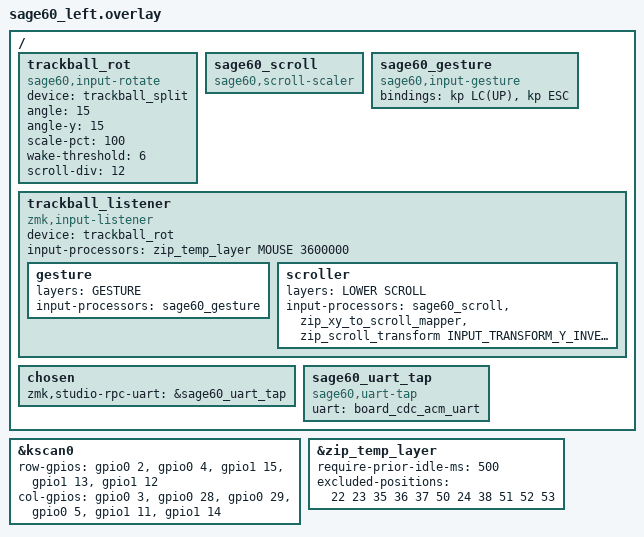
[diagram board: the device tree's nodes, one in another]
/*
 * Copyright (c) 2026 Diwamoto_
 * SPDX-License-Identifier: MIT
 *
 * Sage60 MX - left half (central)
 * Source: pcb/mx_main/mx.kicad_sch  (XIAO nRF52840 = U1)
 *
 *  COL0 -> U1/2  P0.03 (D1)      ROW0 -> U1/1  P0.02 (D0)
 *  COL1 -> U1/3  P0.28 (D2)      ROW1 -> U1/5  P0.04 (D4)
 *  COL2 -> U1/4  P0.29 (D3)      ROW2 -> U1/11 P1.15 (D10)
 *  COL3 -> U1/6  P0.05 (D5)      ROW3 -> U1/9  P1.13 (D8)
 *  COL4 -> U1/7  P1.11 (D6)      ROW4 -> U1/8  P1.12 (D7)
 *  COL5 -> U1/10 P1.14 (D9)
 *
 * diode-direction = col2row  ->  columns are driven (outputs),
 *                                rows are sensed (inputs, pull-down).
 */

#include "sage60.dtsi"
#include <input/processors.dtsi>
#include <dt-bindings/zmk/input_transform.h>
#include <behaviors.dtsi>
#include <dt-bindings/zmk/keys.h>

&kscan0 {
    row-gpios
        = <&gpio0  2 (GPIO_ACTIVE_HIGH | GPIO_PULL_DOWN)>   /* ROW0 P0.02 */
        , <&gpio0  4 (GPIO_ACTIVE_HIGH | GPIO_PULL_DOWN)>   /* ROW1 P0.04 */
        , <&gpio1 15 (GPIO_ACTIVE_HIGH | GPIO_PULL_DOWN)>   /* ROW2 P1.15 */
        , <&gpio1 13 (GPIO_ACTIVE_HIGH | GPIO_PULL_DOWN)>   /* ROW3 P1.13 */
        , <&gpio1 12 (GPIO_ACTIVE_HIGH | GPIO_PULL_DOWN)>   /* ROW4 P1.12 */
        ;

    col-gpios
        = <&gpio0  3 GPIO_ACTIVE_HIGH>   /* COL0 P0.03 */
        , <&gpio0 28 GPIO_ACTIVE_HIGH>   /* COL1 P0.28 */
        , <&gpio0 29 GPIO_ACTIVE_HIGH>   /* COL2 P0.29 */
        , <&gpio0  5 GPIO_ACTIVE_HIGH>   /* COL3 P0.05 */
        , <&gpio1 11 GPIO_ACTIVE_HIGH>   /* COL4 P1.11 */
        , <&gpio1 14 GPIO_ACTIVE_HIGH>   /* COL5 P1.14 */
        ;
};

/* Layer numbers from sage60.keymap. */
#define LOWER  1
#define MOUSE  4
#define SCROLL 5
#define GESTURE 6

/* Moving the ball turns on MOUSE and it stays on (1 h timeout, i.e. never in
 * practice) until a key outside the mouse keys (L back, P forward, ; left,
 * | right, ' scroll, / gesture) and the modifiers (Ctrl, both
 * Shifts, Alt, Cmd, for Cmd-click etc.) is pressed. Typing blocks it for
 * 500 ms so a nudged ball doesn't hijack the home row. */
&zip_temp_layer {
    require-prior-idle-ms = <500>;
    excluded-positions = <22 23 35 36 37 50 /* mouse keys */
                          24 38 51 52 53>; /* LCTRL LSHFT RSHFT LALT LGUI */
};

/ {
    /* The hand rolls the ball at a slant, so a "straight" sideways roll
     * drifts vertically. Positive angle turns motion clockwise on screen.
     * These are defaults: case/site/tune.html changes them over USB and the
     * values are kept in flash (settings_reset clears them). */
    trackball_rot: trackball_rot {
        compatible = "sage60,input-rotate";
        device = <&trackball_split>;
        angle = <15>;   /* sideways rolls */
        angle-y = <15>; /* up/down rolls */
        scale-pct = <100>;
        /* Ignore the first few counts after the ball rests, so typing
         * vibration doesn't nudge the cursor. Raise if it still does. */
        wake-threshold = <6>;
        scroll-div = <12>; /* ball counts per scroll step, lower is faster */
    };

    sage60_scroll: sage60_scroll {
        compatible = "sage60,scroll-scaler";
        #input-processor-cells = <0>;
    };

    /* Hold / and roll up for Mission Control, down for Esc. */
    sage60_gesture: sage60_gesture {
        compatible = "sage60,input-gesture";
        #input-processor-cells = <0>;
        bindings = <&kp LC(UP)>, <&kp ESC>;
    };

    trackball_listener {
        compatible = "zmk,input-listener";
        device = <&trackball_rot>;
        input-processors = <&zip_temp_layer MOUSE 3600000>;

        gesture {
            layers = <GESTURE>;
            input-processors = <&sage60_gesture>;
        };

        /* While Lower or the scroll key below ; is held, the ball scrolls.
         * Speed is scroll-div above (tunable from case/site/tune.html). */
        scroller {
            layers = <LOWER SCROLL>;
            input-processors = <&sage60_scroll>, <&zip_xy_to_scroll_mapper>,
                               <&zip_scroll_transform INPUT_TRANSFORM_Y_INVERT>;
        };
    };
};

/* One USB serial port (the board's own CDC ACM) shared by ZMK Studio and
 * case/site/tune.html through the tap in rotate/input_rotate.c. */
/ {
    chosen {
        zmk,studio-rpc-uart = &sage60_uart_tap;
    };

    sage60_uart_tap: sage60_uart_tap {
        compatible = "sage60,uart-tap";
        uart = <&board_cdc_acm_uart>;
    };
};
